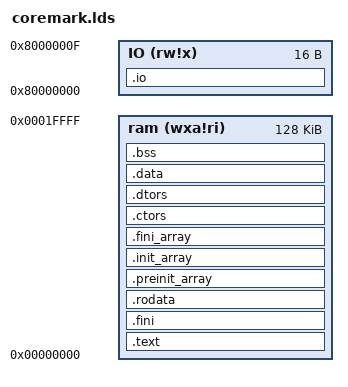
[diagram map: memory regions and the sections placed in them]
/*
This is free and unencumbered software released into the public domain.

Anyone is free to copy, modify, publish, use, compile, sell, or
distribute this software, either in source code form or as a compiled
binary, for any purpose, commercial or non-commercial, and by any
means.
*/
OUTPUT_ARCH( "riscv" )

ENTRY( _boot )

MEMORY
{
    IO  (rw!x)   : ORIGIN = 0x80000000, LENGTH = 0x10
    ram (wxa!ri) : ORIGIN = 0x00000000, LENGTH = 0x20000
}

SECTIONS
{
  .text           :
  {
      *(.boot)
    *(.text.unlikely .text.unlikely.*)
    *(.text.startup .text.startup.*)
    *(.text .text.*)
    *(.gnu.linkonce.t.*)
  } >ram

  .fini           :
  {
    KEEP (*(SORT_NONE(.fini)))
  } >ram

  .rodata         :
  {
    *(.rdata)
    *(.rodata .rodata.*)
    *(.gnu.linkonce.r.*)
  } >ram


  .preinit_array  :
  {
    PROVIDE_HIDDEN (__preinit_array_start = .);
    KEEP (*(.preinit_array))
    PROVIDE_HIDDEN (__preinit_array_end = .);
  } >ram

  .init_array     :
  {
    PROVIDE_HIDDEN (__init_array_start = .);
    KEEP (*(SORT_BY_INIT_PRIORITY(.init_array.*) SORT_BY_INIT_PRIORITY(.ctors.*)))
    KEEP (*(.init_array EXCLUDE_FILE (*crtbegin.o *crtbegin?.o *crtend.o *crtend?.o ) .ctors))
    PROVIDE_HIDDEN (__init_array_end = .);
  } >ram

  .fini_array     :
  {
    PROVIDE_HIDDEN (__fini_array_start = .);
    KEEP (*(SORT_BY_INIT_PRIORITY(.fini_array.*) SORT_BY_INIT_PRIORITY(.dtors.*)))
    KEEP (*(.fini_array EXCLUDE_FILE (*crtbegin.o *crtbegin?.o *crtend.o *crtend?.o ) .dtors))
    PROVIDE_HIDDEN (__fini_array_end = .);
  } >ram

  .ctors          :
  {
    KEEP (*crtbegin.o(.ctors))
    KEEP (*crtbegin?.o(.ctors))
    KEEP (*(EXCLUDE_FILE (*crtend.o *crtend?.o ) .ctors))
    KEEP (*(SORT(.ctors.*)))
    KEEP (*(.ctors))
  } >ram

  .dtors          :
  {
    KEEP (*crtbegin.o(.dtors))
    KEEP (*crtbegin?.o(.dtors))
    KEEP (*(EXCLUDE_FILE (*crtend.o *crtend?.o ) .dtors))
    KEEP (*(SORT(.dtors.*)))
    KEEP (*(.dtors))
  } >ram

  .data          :
  {
    *(.data .data.*)
    *(.gnu.linkonce.d.*)
   _global = . + 0x800;
    *(.sdata .sdata.*)
    *(.gnu.linkonce.s.*)
    *(.srodata.cst16)
    *(.srodata.cst8)
    *(.srodata.cst4)
    *(.srodata.cst2)
    *(.srodata .srodata.*)
  } >ram

  .bss            :
  {
    *(.sbss*)
    *(.gnu.linkonce.sb.*)
    *(.bss .bss.*)
    *(.gnu.linkonce.b.*)
    *(COMMON)
  } >ram
  
  PROVIDE (_stack = ORIGIN(ram) + LENGTH(ram));
  .io : { ./include/io.o(COMMON)} > IO
}
